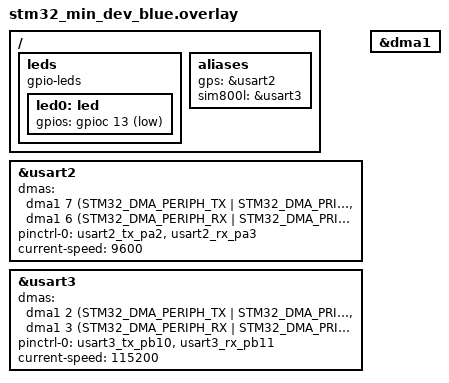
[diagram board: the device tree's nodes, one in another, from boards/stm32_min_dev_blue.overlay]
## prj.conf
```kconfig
# Comunicação

## UART
CONFIG_SERIAL=y # Receber dados do GPS e enviar pro GPRS
CONFIG_UART_ASYNC_API=y # Receber dados de forma assícrona usando Direct Memory Access (DMA)

## CAN
#TODO

# GPIO
CONFIG_GPIO=y # Ativar o controle dos pinos input e output

# Logging
CONFIG_LOG=y # Log de debug (UART 1)

# 3: info, 0: nada
CONFIG_LOG_DEFAULT_LEVEL=3 
```

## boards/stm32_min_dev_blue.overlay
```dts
// Os arquivos .overlay são uma forma abstrata de representar o hardware.
// Cada "escopo" deste arquivo representa uma parte da placa. Note que partes podem
// conter outras partes. AS variáveis que estão sendo atribuídas representam uma característica
// do hardware que está sendo descrito

// Aqui está sendo descrito o escopo "/" (root node). Este escopo representa todo o hardware.
// Note que nos outros escopos abaixo, utilizamos a forma "&(referencia) {}". Isso permite que acessemos
// uma parte da descrição do hardware sem ter que descrever todo o caminho (a partir do root node)
/ {
    // LED da BLuepill
    leds {
        compatible = "gpio-leds";
        led0: led {
            gpios = <&gpioc 13 GPIO_ACTIVE_LOW>;
        };
    };

    // Usado para inicializar aliases de outros devices no código
    aliases {

        // Exemplo
        gps = &usart2;
        sim800l = &usart3; // canal UART de comunicação com o servidor
    };
};

// Exemplo de configuração do USART ASYNC
// WARNING: não utilize o usart1, ele é utilizado pelo LOG
&usart2 {

    // Direct Memory Acess
    // Só é preciso configurá-lo caso você esteja utilizando o UART ASYNC
    // Quando o STM recebe dados pelo usart ele guarda diretamente em uma array
    // definida pelo usuário no código, isso permite que o código não seja
    // travado quando o stm receber dados
    // (https://docs.zephyrproject.org/latest/doxygen/html/group__uart__async.html)

    // Para saber quais canais eu devia usar, eu utilizei o Reference Manual
    // do STM32F103C8T6 (Cada canal de USART usa um diferente)
    // (https://docs.zephyrproject.org/latest/build/dts/api/bindings/dma/st,stm32-dma-v2bis.html)
    dmas = <&dma1 7 (STM32_DMA_PERIPH_TX | STM32_DMA_PRIORITY_HIGH)>,
           <&dma1 6 (STM32_DMA_PERIPH_RX | STM32_DMA_PRIORITY_HIGH)>;
    dma-names = "tx", "rx";

    // Aqui são definidos os pinos do USART 2
    // (https://docs.zephyrproject.org/latest/boards/others/stm32_min_dev/doc/index.html#id2)
    pinctrl-0 = <&usart2_tx_pa2 &usart2_rx_pa3>;    //NOTE:
                                                    // TX: PA2
                                                    // RX: PA3
    // Não mudar
    pinctrl-names = "default";

    // Baudrate do USART2
    current-speed = <9600>;
    status = "okay";
};

// Ativando o Direct Memory Access
&dma1 {
    status = "okay";
};

// TODO: Criar uma configuração de CAN

/* vim: set filetype=dts : */

&usart3 {

    // Direct Memory Acess
    // Só é preciso configurá-lo caso você esteja utilizando o UART ASYNC
    // Quando o STM recebe dados pelo usart ele guarda diretamente em uma array
    // definida pelo usuário no código, isso permite que o código não seja
    // travado quando o stm receber dados
    // (https://docs.zephyrproject.org/latest/doxygen/html/group__uart__async.html)

    // Para saber quais canais eu devia usar, eu utilizei o Reference Manual
    // do STM32F103C8T6 (Cada canal de USART usa um diferente)
    // (https://docs.zephyrproject.org/latest/build/dts/api/bindings/dma/st,stm32-dma-v2bis.html)
    dmas = <&dma1 2 (STM32_DMA_PERIPH_TX | STM32_DMA_PRIORITY_HIGH)>,
           <&dma1 3 (STM32_DMA_PERIPH_RX | STM32_DMA_PRIORITY_HIGH)>;
    dma-names = "tx", "rx";

    // Aqui são definidos os pinos do USART 2
    // (https://docs.zephyrproject.org/latest/boards/others/stm32_min_dev/doc/index.html#id2)
    pinctrl-0 = <&usart3_tx_pb10 &usart3_rx_pb11>;    //NOTE:
                                                    // TX: PA2
                                                    // RX: PA3
    // Não mudar
    pinctrl-names = "default";

    // Baudrate do USART2
    current-speed = <115200>;
    status = "okay";
};
```

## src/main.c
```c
#include "zephyr/device.h"
#include "zephyr/sys/printk.h"
#include "zephyr/logging/log.h"
#include <zephyr/drivers/gpio.h>
#include <zephyr/kernel.h>
#include "SIM800L.h"


LOG_MODULE_REGISTER();

int main(){
  init_server(11547, TIM);

  while(1){
    send_server("oi");
    k_msleep(1);
  }
}
```

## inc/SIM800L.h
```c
#ifndef SIM800L_H
#define SIM800L_H

#include "zephyr/drivers/uart.h"

enum OPERADORA{TIM, VIVO, CLARO, OUTRO};

/**
 * @struct s_server
 * @brief Representa a conexão UART com o SIM800L
 */
struct s_server{
    /** Referência ao device da device tree que representa o canal UART sendo usado*/
    const struct device *dev;
    /** Buffer no qual serão registradas mensagens recebidas através de callback*/
    char *buffer;
    /** Número de caracteres do buffer que armazena as mensagens recebidas por callback*/
    int buffer_size;
    /** Booleano que registra se há conexão com o servidor*/
    bool connected;
};

/**
 * @brief Estabelece o canal de comunicação UART do STM com o SIM800L e estabelece uma conexão entre o SIM800L e o servidor
 * @param port Porta do servidor
 * @param op Operadora do chip sendo usado
 */
int init_server(unsigned int port, enum OPERADORA op);

/**
 * @brief Envia uma mensagem ao servidor
 * @param message Mensagem a ser enviada ao servidor
 */
void send_server(char *message);

#endif
```

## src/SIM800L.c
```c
#include "SIM800L.h"
#include <stdlib.h>
#include <zephyr/kernel.h>
#include <string.h>
#include <zephyr/logging/log.h>

LOG_MODULE_DECLARE();

struct s_server server; //UART3

static void server_callback(const struct device *dev, struct uart_event *evt, void *user_data);

void uart_poll_out_str(const struct device *dev, unsigned char *out_str, unsigned int len){
    for(int i = 0; i < len; i++){
        uart_poll_out(dev, out_str[i]);
    }
}

int init_server(unsigned int port, enum OPERADORA op){
    // Inicializando a comunicação UART
    server.dev = DEVICE_DT_GET(DT_ALIAS(sim800l));
    server.buffer_size = 50;
    server.buffer = calloc(50, sizeof(char));
    memset(server.buffer, '.', 50);
    server.connected = false;

    {
    LOG_INF("setando callback do sim800L");
    int ret = uart_callback_set(server.dev, server_callback, NULL);
    if(ret)
    {
        LOG_ERR("erro ao setar callback");
        printk("%d", ret);
        return ret;
    } 
    LOG_INF("Habilitando rx sim800L");
    uart_rx_enable(server.dev, server.buffer, server.buffer_size, 1000);
    }

    char temp[100];

    // TODO: substituir o delay por uma verificação de conexão
    LOG_INF("[SIM800L]: teste AT");
    sprintf(temp, "AT\r\n");
    uart_poll_out_str(server.dev, temp, strlen(temp));

    k_msleep(10000);

    // Select TCIP Application Mode
    LOG_INF("Select TCIP Application Mode");
    sprintf(temp, "AT+CIPMODE=0\r\n");
    uart_poll_out_str(server.dev, temp, strlen(temp));
    k_msleep(1000);

    // Startup single IP connection
    LOG_INF("Startup single IP connection");
	sprintf(temp, "AT+CIPMUX=0\r\n");
    uart_poll_out_str(server.dev, temp, strlen(temp));
    k_msleep(1000);

	// Attach from GPRS Service
    LOG_INF("Attach from GPRS Service");
	sprintf(temp, "AT+CGATT=1\r\n");
    uart_poll_out_str(server.dev, temp, strlen(temp));
    k_msleep(1000);

	// Start task and set APN
    LOG_INF("Start task and set APN");
    switch(op){
        case VIVO:
            sprintf(temp, "AT+CSTT=\"zap.vivo.com.br\",\"Vivo ZAP\",\"Vivo ZAP\"\r\n");
            break;
        case TIM:
            sprintf(temp, "AT+CSTT=\"timbrasil.br\",\"tim\",\"tim\"\r\n");
            break;
        case CLARO:
            sprintf(temp, "AT+CSTT=\"java.claro.com.br\",\"Claro\",\"Claro\"\r\n");
            break;
        case OUTRO:
            sprintf(temp, "AT+CSTT=\"[arg1]\",\"[arg2]\",\"[arg3]\"\r\n");
            break;
    }
    uart_poll_out_str(server.dev, temp, strlen(temp));
    k_msleep(3000);

	// Bring up wireless connection with GPRS  or CSD
    LOG_INF("Bring up wireless connection with GPRS  or CSD");
	sprintf(temp, "AT+CIICR\r\n");
    uart_poll_out_str(server.dev, temp, strlen(temp));
    k_msleep(3000);

	// Get Local IP address
    LOG_INF("Get Local IP address");
	sprintf(temp, "AT+CIFSR\r\n");
    uart_poll_out_str(server.dev, temp, strlen(temp));
    k_msleep(1000);

	// Start up TCP connection
    LOG_INF("Start up TCP connection");
	sprintf(temp, "AT+CIPSTART=\"TCP\",\"0.tcp.sa.ngrok.io\",\"%05d\"\r\n", port);
    uart_poll_out_str(server.dev, temp, strlen(temp));
    server.connected = true;
    k_msleep(5000);


	// Enviar mensagem pro servidor que é o baja que tá conectando
    LOG_INF("Enviar mensagem pro servidor que é o baja que tá conectando");
    send_server("[CONNECTION] Baja");

    return 0;
}

void send_server(char *message){
    char temp[100];

    sprintf(temp, "AT+CIPSEND=%d\r\n", strlen(message));
    uart_poll_out_str(server.dev, temp, strlen(temp));
    k_msleep(1000);

    sprintf(temp, "%s\r\n", message);
    uart_poll_out_str(server.dev, temp, strlen(temp));
    k_msleep(1000);
}

void server_callback(const struct device *dev, struct uart_event *evt, void *user_data){
    switch(evt->type){
        case UART_RX_RDY:
            char msg[100];
            //sscanf(evt->data.rx.buf, " %[^\r]", msg);
            printk("Mensagem recebida: [%.50s]\n", evt->data.rx.buf);
            uart_rx_disable(dev);
            break;

        case UART_RX_DISABLED:
            //printk("disabled");
            memset(server.buffer, '.', 50);
            uart_rx_enable(server.dev, server.buffer, server.buffer_size, 1000);
            break;
    }
}
```
